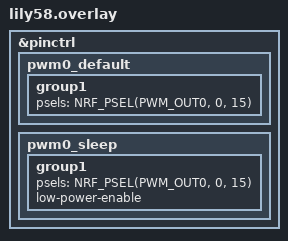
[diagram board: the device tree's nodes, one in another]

&pinctrl {
    // Other pinctrl definitions for other hardware
    pwm0_default: pwm0_default {
        group1 {
            psels = <NRF_PSEL(PWM_OUT0, 0, 15)>;
        };
    };
    pwm0_sleep: pwm0_sleep {
        group1 {
            psels = <NRF_PSEL(PWM_OUT0, 0, 15)>;
            low-power-enable;
        };
    };
};
